# H3 register map
Vendor: Allwinner; Series: H3; File version: 0.1
CPU: 0, little endian, MPU, no FPU, 0 interrupt priority bits
Registers are 32-bit, read-write, reset 0x0 unless marked. A register's access mark holds for its fields unless they carry their own. Offsets are from the block's base; [hi:lo] are bit positions; lines under a group give offsets from that group; {n}, {i} and the like mark numbered series; 'fields as' and 'values as' point back to an identical list; <NAME> marks a mode.

## I2S/PCM_0
Base 0x01C22000
Same registers: I2S/PCM_1 0x01C22400, I2S/PCM_2 0x01C22800
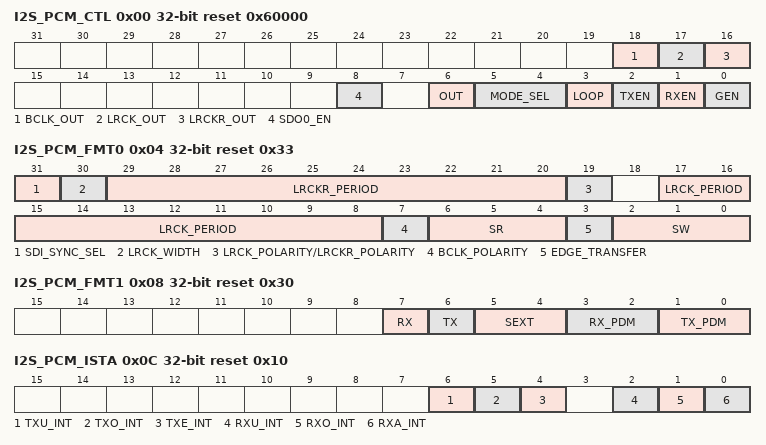
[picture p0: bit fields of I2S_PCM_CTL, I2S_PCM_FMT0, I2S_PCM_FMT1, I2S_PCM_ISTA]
0x00 I2S_PCM_CTL reset 0x60000
  [18] BCLK_OUT — 0: input 1: output
    0=input; 1=output
  [17] LRCK_OUT — 0: input 1: output
    0=input; 1=output
  [16] LRCKR_OUT — 0: input 1: output
    0=input; 1=output
  [8] SDO0_EN — 0: Disable, Hi-Z state 1: Enable
    0=Disable, Hi-Z state; 1=Enable
  [6] OUT — Mute 0: normal transfer 1: force DOUT to output 0
    0=normal transfer; 1=force DOUT to output 0
  [5:4] MODE_SEL — Mode Selection 0: PCM mode (offset 0: DSP_B; offset 1: DSP_A) 1: Left mode (offset 0: LJ mode; offset 1: I2S mode) 2: Right-Justified mode 3: Reserved
    2=right_Justified_mode
  [3] LOOP — Loop back test 0: Normal mode 1: Loop back test When set `1`, connecting the SDO0 with the SDI
    0=Normal_mode; 1=Loop back test When set `1`, connecting the SDO0 with the SDI
  [2] TXEN — Transmitter Block Enable 0: Disable 1: Enable
    0=Disable; 1=Enable
  [1] RXEN — Receiver Block Enable 0: Disable 1: Enable
    0=Disable; 1=Enable
  [0] GEN — Globe Enable A disable on this bit overrides any other block or channel enables. 0: Disable 1: Enable
    0=Disable; 1=Enable
0x04 I2S_PCM_FMT0 reset 0x33
  [31] SDI_SYNC_SEL — 0: SDI use LRCK 1: SDI use LRCKR
    0=SDI_use_LRCK; 1=SDI_use_LRCKR
  [30] LRCK_WIDTH — (only apply in PCM mode ) LRCK width 0: LRCK = 1 BCLK width (short frame) 1: LRCK = 2 BCLK width (long frame)
    0=LRCK__equals__1 (LRCK = 1 BCLK width (short frame)); 1=LRCK__equals__2 (LRCK = 2 BCLK width (long frame))
  [29:20] LRCKR_PERIOD — It is used to program the number of BCLKs per channel of sample frame. This value is interpreted as follow: PCM mode: Number of BCLKs within (Left + Right) channel width I2S / Left-Justified / Right-Justified mode: Number of BCLKs within each individual channel width (Left or Right) N+1 For example: n = 7: 8 BCLK width ... n = 1023: 1024 BCLKs width
  [19] LRCK_POLARITY/LRCKR_POLARITY — When apply in I2S / Left-Justified / Right-Justified mode: 0: Left channel when LRCK is low 1: Left channel when LRCK is high When apply in PCM mode: 0: PCM LRCK/LRCKR asserted at the negative edge 1: PCM LRCK/LRCKR asserted at the positive edge
    0=low (Left channel when LRCK is low); 1=high (Left channel when LRCK is high When apply in PCM mode:); 0=PCM_LRCK_slash_LRCKR_asserted_at_the_negative (PCM LRCK/LRCKR asserted at the negative edge); 1=PCM_LRCK_slash_LRCKR_asserted_at_the_positive (PCM LRCK/LRCKR asserted at the positive edge)
  [17:8] LRCK_PERIOD — It is used to program the number of BCLKs per channel of sample frame. This value is interpreted as follow: PCM mode: Number of BCLKs within (Left + Right) channel width I2S / Left-Justified / Right-Justified mode: Number of BCLKs within each individual channel width (Left or Right) N+1 For example: n = 7: 8 BCLK width ... n = 1023: 1024 BCLKs width
  [7] BCLK_POLARITY — 0: normal mode, negative edge drive and positive edge sample 1: invert mode, positive edge drive and negative edge sample
    0=normal mode, negative edge drive and positive edge sample; 1=invert mode, positive edge drive and negative edge sample
  [6:4] SR — Sample Resolution 0: Reserved 1: 8-bit 2: 12-bit 3: 16-bit 4: 20-bit 5: 24-bit 6: 28-bit 7: 32-bit
    2=_12_bit; 3=_16_bit; 4=_20_bit; 5=_24_bit; 6=_28_bit; 7=_32_bit
  [3] EDGE_TRANSFER — 0: SDO drive data and SDI sample data at the different BCLK edge 1: SDO drive data and SDI sample data at the same BCLK edge BCLK_POLARITY = 0, use negative edge BCLK_POLARITY = 1, use positive edge
    0=SDO drive data and SDI sample data at the different BCLK edge; 1=SDO drive data and SDI sample data at the same BCLK edge BCLK_POLARITY = 0, use negative edge BCLK_POLARITY = 1, use positive edge
  [2:0] SW — Slot Width Select 0: Reserved 1: 8-bit 2: 12-bit 3: 16-bit 4: 20-bit 5: 24-bit 6: 28-bit 7: 32-bit
    values as SR
0x08 I2S_PCM_FMT1 reset 0x30
  [7] RX — MLS MSB / LSB First Select 0: MSB First 1: LSB First
    0=MSB (MSB First); 1=LSB (LSB First)
  [6] TX — MLS MSB / LSB First Select 0: MSB First 1: LSB First
    0=MSB (MSB First); 1=LSB (LSB First)
  [5:4] SEXT — Sign Extend in slot [sample resolution < slot width] 0: Zeros or audio gain padding at LSB position 1: Sign extension at MSB position 2: Reserved 3: Transfer 0 after each sample in each slot
    3=Transfer 0 after each sample in each slot
  [3:2] RX_PDM — PCM Data Mode 0: Linear PCM 1: reserved 2: 8-bits u-law 3: 8-bits A-law
    2=_8_bits_ulaw; 3=_8_bits_Alaw
  [1:0] TX_PDM — PCM Data Mode 0: Linear PCM 1: reserved 2: 8-bits u-law 3: 8-bits A-law
    2=_8_bits_ulaw; 3=_8_bits_Alaw
0x0C I2S_PCM_ISTA reset 0x10
  [6] TXU_INT — TX FIFO Under run Pending Interrupt 0: No Pending Interrupt 1: FIFO Under run Pending Interrupt Write 1 to clear this interrupt
    0=No Pending Interrupt; 1=FIFO (FIFO Under run Pending Interrupt Write 1 to clear this interrupt)
  [5] TXO_INT — TX FIFO Overrun Pending Interrupt 0: No Pending Interrupt 1: FIFO Overrun Pending Interrupt Write `1` to clear this interrupt
    0=No Pending Interrupt; 1=FIFO (FIFO Overrun Pending Interrupt Write `1` to clear this interrupt)
  [4] TXE_INT — TX FIFO Empty Pending Interrupt 0: No Pending IRQ 1: FIFO Empty Pending Interrupt when data in TX FIFO are less than TX trigger level Write `1` to clear this interrupt or automatic clear if interrupt condition fails.
    0=No Pending IRQ; 1=FIFO (FIFO Empty Pending Interrupt when data in TX FIFO are less than TX trigger level Write `1` to clear this interrupt or automatic clear if interrupt condition fails.)
  [2] RXU_INT — RX FIFO Under run Pending Interrupt 0: No Pending Interrupt 1:FIFO Under run Pending Interrupt Write 1 to clear this interrupt
    0=No Pending Interrupt 1:FIFO Under run Pending Interrupt Write 1 to clear this interrupt
  [1] RXO_INT — RX FIFO Overrun Pending Interrupt 0: No Pending IRQ 1: FIFO Overrun Pending IRQ Write `1` to clear this interrupt
    0=No Pending IRQ; 1=FIFO (FIFO Overrun Pending IRQ Write `1` to clear this interrupt)
  [0] RXA_INT — RX FIFO Data Available Pending Interrupt 0: No Pending IRQ 1: Data Available Pending IRQ when data in RX FIFO are more than RX trigger level Write `1` to clear this interrupt or automatic clear if interrupt condition fails.
    0=No Pending IRQ; 1=Data Available Pending IRQ when data in RX FIFO are more than RX trigger level Write `1` to clear this interrupt or automatic clear if interrupt condition fails
0x10 I2S_PCM_RXFIFO
  [31:0] RX_DATA ro — RX Sample Host can get one sample by reading this register. The left channel sample data is first and then the right channel sample.
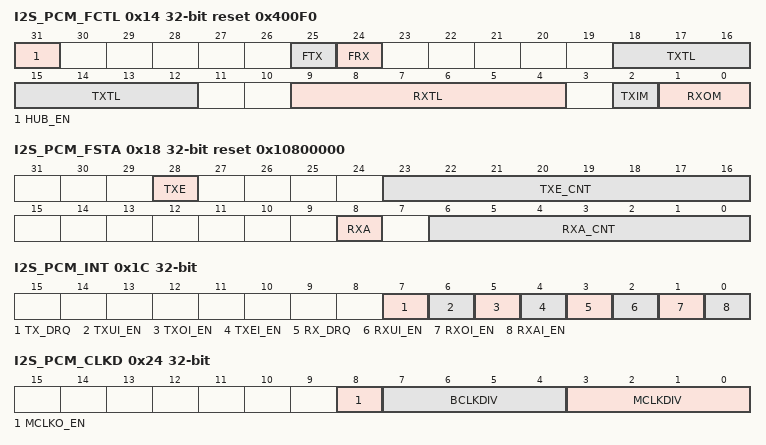
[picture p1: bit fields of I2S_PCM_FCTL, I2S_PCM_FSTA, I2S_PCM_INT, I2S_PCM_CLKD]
0x14 I2S_PCM_FCTL reset 0x400F0
  [31] HUB_EN — Audio hub enable 0:disable 1:enable
  [25] FTX — Write `1` to flush TX FIFO, self clear to `0`.
  [24] FRX — Write `1` to flush RX FIFO, self clear to `0`.
  [18:12] TXTL — TX FIFO Empty Trigger Level Interrupt and DMA request trigger level for TXFIFO normal condition Trigger Level = TXTL
  [9:4] RXTL — RX FIFO Trigger Level Interrupt and DMA request trigger level for RXFIFO normal condition Trigger Level = RXTL + 1
  [2] TXIM — TX FIFO Input Mode (Mode 0, 1) 0: Valid data at the MSB of TXFIFO register 1: Valid data at the LSB of TXFIFO register Example for 20-bits transmitted audio sample: Mode 0: FIFO_I[31:0] = {APB_WDATA[31:12], 12`h0} Mode 1: FIFO_I[31:0] = {APB_WDATA[19:0], 12`h0}
    0=Valid data at the MSB of TXFIFO register; 1=Valid data at the LSB of TXFIFO register Example for 20-bits transmitted audio sample: Mode 0: FIFO_I[31:0] = {APB_WDATA[31:12], 12`h0} Mode 1: FIFO_I[31:0] = {APB_WDATA[19:0], 12`h0}
  [1:0] RXOM — RX FIFO Output Mode (Mode 0, 1, 2, 3) 00: Expanding `0` at LSB of DA_RXFIFO register. 01: Expanding received sample sign bit at MSB of DA_RXFIFO register. 10: Truncating received samples at high half-word of DA_RXFIFO register and low half-word of DA_RXFIFO register is filled by `0`. 11: Truncating received samples at low half-word of DA_RXFIFO register and high half-word of DA_RXFIFO register is expanded by its sign bit. Example for 20-bits received audio sample: Mode 0: APB_RDATA[31:0] = {FIFO_O[31:12], 12`h0} Mode 1: APB_RDATA [31:0] = {12{FIFO_O[31]}, FIFO_O[31:12]} Mode 2: APB_RDATA [31:0] = {FIFO_O[31:16], 16`h0} Mode 3: APB_RDATA [31:0] = {16{FIFO_O[31], FIFO_O[31:16]}
    0=Expanding `0` at LSB of DA_RXFIFO register; 1=Expanding received sample sign bit at MSB of DA_RXFIFO register; 2=Truncating received samples at high half-word of DA_RXFIFO register and low half-word of DA_RXFIFO register is filled by `0`; 3=Truncating received samples at low half-word of DA_RXFIFO register and high half-word of DA_RXFIFO register is expanded by its sign bit. Example for 20-bits received audio sample: Mode 0: APB_RDATA[31:0] = {FIFO_O[31:12], 12`h0} Mode 1: APB_RDATA [31:0] = {12{FIFO_O[31]}, FIFO_O[31:12]} Mode 2: APB_RDATA [31:0] = {FIFO_O[31:16], 16`h0} Mode 3: APB_RDATA [31:0] = {16{FIFO_O[31], FIFO_O[31:16]}
0x18 I2S_PCM_FSTA reset 0x10800000
  [28] TXE ro — TX FIFO Empty 0: No room for new sample in TX FIFO 1: More than one room for new sample in TX FIFO (>= 1 word)
    0=No room for new sample in TX FIFO; 1=More than one room for new sample in TX FIFO (>= 1 word)
  [23:16] TXE_CNT ro — TX FIFO Empty Space Word Counter
  [8] RXA ro — RX FIFO Available 0: No available data in RX FIFO 1: More than one sample in RX FIFO (>= 1 word)
    0=No available data in RX FIFO; 1=More than one sample in RX FIFO (>= 1 word)
  [6:0] RXA_CNT ro — RX FIFO Available Sample Word Counter
0x1C I2S_PCM_INT
  [7] TX_DRQ — TX FIFO Empty DRQ Enable 0: Disable 1: Enable
    0=Disable; 1=Enable
  [6] TXUI_EN — TX FIFO Under run Interrupt Enable 0: Disable 1: Enable
    0=Disable; 1=Enable
  [5] TXOI_EN — TX FIFO Overrun Interrupt Enable 0: Disable 1: Enable When set to `1`, an interrupt happens when writing new audio data if TX FIFO is full.
    0=Disable; 1=Enable When set to `1`, an interrupt happens when writing new audio data if TX FIFO is full
  [4] TXEI_EN — TX FIFO Empty Interrupt Enable 0: Disable 1: Enable
    0=Disable; 1=Enable
  [3] RX_DRQ — RX FIFO Data Available DRQ Enable 0: Disable 1: Enable When set to `1`, RXFIFO DMA Request line is asserted if Data is available in RX FIFO.
    0=Disable; 1=Enable When set to `1`, RXFIFO DMA Request line is asserted if Data is available in RX FIFO
  [2] RXUI_EN — RX FIFO Under run Interrupt Enable 0: Disable 1: Enable
    0=Disable; 1=Enable
  [1] RXOI_EN — RX FIFO Overrun Interrupt Enable 0: Disable 1: Enable
    0=Disable; 1=Enable
  [0] RXAI_EN — RX FIFO Data Available Interrupt Enable 0: Disable 1: Enable
    0=Disable; 1=Enable
0x20 I2S_PCM_TXFIFO
  [31:0] TX_DATA wo — TX Sample Transmitting left, right channel sample data should be written this register one by one. The left channel sample data is first and then the right channel sample.
0x24 I2S_PCM_CLKD
  [8] MCLKO_EN — 0: Disable MCLK Output 1: Enable MCLK Output Notes: Whether in Slave or Master mode, when this bit is set to 1, MCLK should be output.
    0=Disable MCLK Output; 1=Enable MCLK Output Notes: Whether in Slave or Master mode, when this bit is set to 1, MCLK should be output
  [7:4] BCLKDIV — BCLK Divide Ratio from PLL2 0: reserved 1: Divide by 1 2: Divide by 2 3: Divide by 4 4: Divide by 6 5: Divide by 8 6: Divide by 12 7: Divide by 16 8: Divide by 24 9: Divide by 32 10: Divide by 48 11: Divide by 64 12: Divide by 96 13: Divide by 128 14: Divide by 176 15: Divide by 192
    2=Divide_by_2; 3=Divide_by_4; 4=Divide_by_6; 5=Divide_by_8; 6=Divide_by_12; 7=Divide_by_16; 8=Divide_by_24; 9=Divide_by_32; 12=Divide_by_96; 13=Divide_by_128; 14=Divide_by_176; 15=Divide_by_192
  [3:0] MCLKDIV — MCLK Divide Ratio from PLL2 Output 0: reserved 1: Divide by 1 2: Divide by 2 3: Divide by 4 4: Divide by 6 5: Divide by 8 6: Divide by 12 7: Divide by 16 8: Divide by 24 9: Divide by 32 10: Divide by 48 11: Divide by 64 12: Divide by 96 13: Divide by 128 14: Divide by 176 15: Divide by 192
    values as BCLKDIV
0x28 I2S_PCM_TXCNT
  [31:0] TX_CNT — TX Sample Counter The audio sample number of sending into TXFIFO. When one sample is put into TXFIFO by DMA or by host IO, the TX sample counter register increases by one. The TX sample counter register can be set to any initial valve at any time. After been updated by the initial value, the counter register should count on base of this initial value.
0x2C I2S_PCM_RXCNT
  [31:0] RX_CNT — RX Sample Counter The audio sample number of writing into RXFIFO. When one sample is written by Digital Audio Engine, the RX sample counter register increases by one. The RX sample counter register can be set to any initial valve at any time. After been updated by the initial value, the counter register should count on base of this initial value.
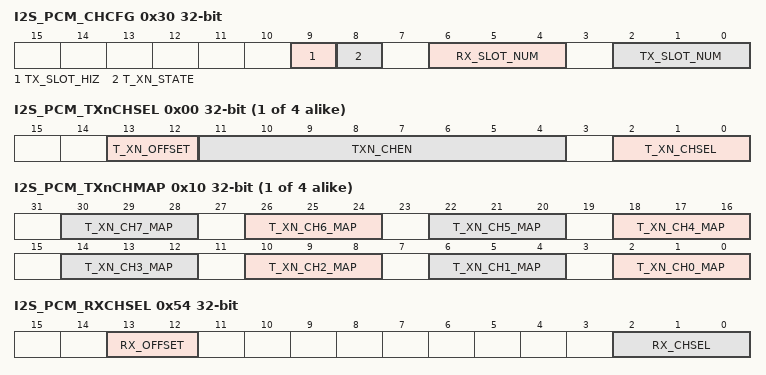
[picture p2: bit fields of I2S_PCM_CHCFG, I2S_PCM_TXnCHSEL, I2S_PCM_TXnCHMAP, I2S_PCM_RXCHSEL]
0x30 I2S_PCM_CHCFG
  [9] TX_SLOT_HIZ — 0: normal mode for the last half cycle of BCLK in the slot 1: turn to hi-z state for the last half cycle of BCLK in the slot
    0=normal mode for the last half cycle of BCLK in the slot; 1=turn to hi-z state for the last half cycle of BCLK in the slot
  [8] T_XN_STATE — TXn_STATE 0: transfer level 0 when not transferring slot 1: turn to hi-z state when not transferring slot
    0=transfer level 0 when not transferring slot; 1=turn to hi-z state when not transferring slot
  [6:4] RX_SLOT_NUM — RX Channel/Slot Number which between CPU/DMA and FIFO 0: 1 channel or slot ... 7: 8 channels or slots
    7=8 channels or slots
  [2:0] TX_SLOT_NUM — TX Channel/Slot Number which between CPU/DMA and FIFO 0: 1 channel or slot ... 7: 8 channels or slots
    7=8 channels or slots
{0x34+4i} _n[{i}] (i=0..3) group
  0x00 I2S_PCM_TXnCHSEL
    [13:12] T_XN_OFFSET — TXn_OFFSET TXn offset tune, TXn data offset to LRCK 0: no offset n: data is offset by n BCLKs to LRCK
    [11:4] TXN_CHEN — TXn_CHEN TXn Channel (slot) enable, bit[11:4] refer to slot [7:0]. When one or more slot(s) is(are) disabled, the affected slot(s) is(are) set to disable state 0: disable 1: enable
    [2:0] T_XN_CHSEL — TXn_CHSEL TXn Channel (slot) number Select for each output 0: 1 channel / slot ... 7: 8 channels / slots
      7=8 channels / slots
  0x10 I2S_PCM_TXnCHMAP
    [all] fields
      7=_8th_sample
    [4n+2:4n] T_XN_CH{n}_MAP (n=0..7) — TXn_CH{n}_MAP TXn Channel{n} Mapping 0: 1st sample ... 7: 8th sample
0x54 I2S_PCM_RXCHSEL
  [13:12] RX_OFFSET — RX offset tune, RX data offset to LRCK 0: no offset n: data is offset by n BCLKs to LRCK
  [2:0] RX_CHSEL — RX Channel (slot) number Select for input 0: 1 channel / slot ... 7: 8 channels / slots
    7=8 channels / slots
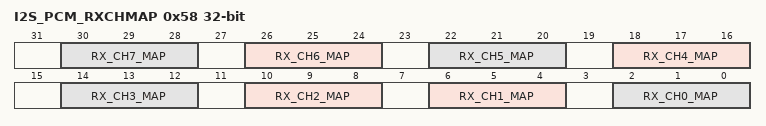
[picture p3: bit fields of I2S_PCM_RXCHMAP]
0x58 I2S_PCM_RXCHMAP
  [all] fields
    7=_8th_sample
  [4n+2:4n] RX_CH{n}_MAP (n=2..7) — RX Channel{n} Mapping 0: 1st sample ... 7: 8th sample
  [6:4] RX_CH1_MAP — TX Channel1 Mapping 0: 1st sample ... 7: 8th sample
  [2:0] RX_CH0_MAP — RX Channel0 Mapping 0: 1st sample ... 7: 8th sample
